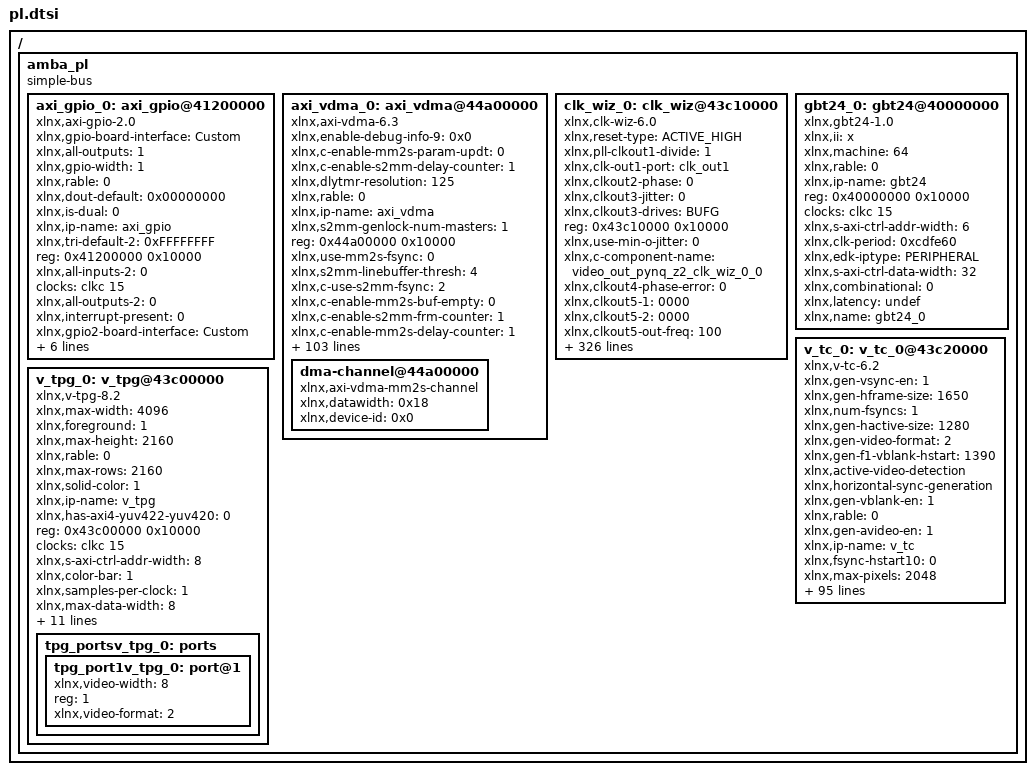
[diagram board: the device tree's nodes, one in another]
/ {
	amba_pl: amba_pl {
		ranges;
		compatible = "simple-bus";
		#address-cells = <1>;
		#size-cells = <1>;
		axi_gpio_0: axi_gpio@41200000 {
			xlnx,gpio-board-interface = "Custom";
			compatible = "xlnx,axi-gpio-2.0" , "xlnx,xps-gpio-1.00.a";
			xlnx,all-outputs = <1>;
			xlnx,gpio-width = <1>;
			xlnx,rable = <0>;
			xlnx,dout-default = <0x00000000>;
			xlnx,is-dual = <0>;
			xlnx,ip-name = "axi_gpio";
			xlnx,tri-default-2 = <0xFFFFFFFF>;
			reg = <0x41200000 0x10000>;
			xlnx,all-inputs-2 = <0>;
			clocks = <&clkc 15>;
			xlnx,all-outputs-2 = <0>;
			xlnx,interrupt-present = <0>;
			xlnx,gpio2-board-interface = "Custom";
			xlnx,edk-iptype = "PERIPHERAL";
			xlnx,dout-default-2 = <0x00000000>;
			xlnx,gpio2-width = <32>;
			status = "okay";
			clock-names = "s_axi_aclk";
			xlnx,tri-default = <0xFFFFFFFF>;
			xlnx,name = "axi_gpio_0";
			xlnx,all-inputs = <0>;
		};
		axi_vdma_0: axi_vdma@44a00000 {
			xlnx,enable-debug-info-9 = <0x0>;
			xlnx,c-enable-mm2s-param-updt = <0>;
			xlnx,c-enable-s2mm-delay-counter = <1>;
			xlnx,dlytmr-resolution = <125>;
			xlnx,rable = <0>;
			xlnx,ip-name = "axi_vdma";
			xlnx,s2mm-genlock-num-masters = <1>;
			reg = <0x44a00000 0x10000>;
			xlnx,use-mm2s-fsync = <0>;
			xlnx,s2mm-linebuffer-thresh = <4>;
			xlnx,c-use-s2mm-fsync = <2>;
			xlnx,c-enable-mm2s-buf-empty = <0>;
			xlnx,c-enable-s2mm-frm-counter = <1>;
			xlnx,c-enable-mm2s-delay-counter = <1>;
			xlnx,c-dlytmr-resolution = <125>;
			xlnx,c-enable-s2mm-buf-full = <0>;
			xlnx,dynamic-resolution = <1>;
			xlnx,s2mm-sof-enable = <0x1>;
			xlnx,mm2s-genlock-num-masters = <1>;
			xlnx,c-s2mm-genlock-num-masters = <1>;
			xlnx,c-enable-s2mm-fsync-out = <0>;
			xlnx,mm2s-linebuffer-thresh = <4>;
			xlnx,c-use-mm2s-fsync = <0>;
			xlnx,c-s2mm-linebuffer-thresh = <4>;
			xlnx,c-enable-mm2s-frm-counter = <1>;
			compatible = "xlnx,axi-vdma-6.3" , "xlnx,axi-vdma-1.00.a";
			xlnx,c-m-axis-mm2s-tdata-width = <24>;
			xlnx,c-enable-all = <0>;
			xlnx,s2mm-max-burst-length = <8>;
			xlnx,c-dynamic-resolution = <1>;
			xlnx,c-enable-s2mm-rst-out = <0>;
			xlnx,mm2s-sof-enable = <1>;
			xlnx,include-s2mm-dre = <0x0>;
			xlnx,c-s2mm-sof-enable = <1>;
			xlnx,c-enable-mm2s-fsync-out = <0>;
			xlnx,c-mm2s-genlock-num-masters = <1>;
			xlnx,c-mm2s-linebuffer-thresh = <4>;
			xlnx,c-enable-tstvec = <0>;
			xlnx,mm2s-max-burst-length = <8>;
			xlnx,c-s2mm-max-burst-length = <8>;
			status = "okay";
			xlnx,c-enable-mm2s-rst-out = <0>;
			xlnx,include-mm2s-dre = <0x0>;
			xlnx,c-include-s2mm-dre = <0>;
			xlnx,c-mm2s-sof-enable = <1>;
			xlnx,name = "axi_vdma_0";
			xlnx,c-enable-s2mm-frmstr-reg = <0>;
			xlnx,c-include-sg = <0>;
			xlnx,flush-on-fsync = <0x1>;
			xlnx,c-m-axi-s2mm-data-width = <64>;
			xlnx,c-enable-s2mm-sts-reg = <0>;
			xlnx,include-s2mm-sf = <1>;
			xlnx,c-mm2s-max-burst-length = <8>;
			xlnx,s2mm-linebuffer-depth = <0x200>;
			xlnx,include-s2mm = <0x0>;
			xlnx,c-include-mm2s-dre = <0>;
			clocks = <&clkc 15>, <&clkc 15>, <&clkc 15>;
			xlnx,c-enable-mm2s-frmstr-reg = <0>;
			xlnx,enable-debug-info-10 = <0>;
			xlnx,addrwidth = <0x20>;
			xlnx,enable-debug-info-11 = <0>;
			xlnx,enable-debug-info-12 = <0>;
			xlnx,edk-iptype = "PERIPHERAL";
			xlnx,c-flush-on-fsync = <1>;
			xlnx,c-m-axi-mm2s-data-width = <64>;
			xlnx,use-fsync = <1>;
			xlnx,s2mm-genlock-repeat-en = <1>;
			xlnx,enable-vert-flip = <0x0>;
			xlnx,enable-debug-info-13 = <0x0>;
			xlnx,include-mm2s-sf = <0>;
			xlnx,include-internal-genlock = <0x1>;
			xlnx,enable-debug-info-14 = <0x1>;
			xlnx,c-include-s2mm-sf = <1>;
			clock-names = "m_axi_mm2s_aclk" , "m_axis_mm2s_aclk" , "s_axi_lite_aclk";
			xlnx,enable-debug-info-15 = <0x1>;
			xlnx,mm2s-linebuffer-depth = <0x200>;
			xlnx,include-mm2s = <0x1>;
			xlnx,c-single-interface = <0>;
			xlnx,c-s2mm-linebuffer-depth = <512>;
			xlnx,c-addr-width = <32>;
			xlnx,c-include-s2mm = <0>;
			xlnx,s2mm-genlock-mode = <0x0>;
			xlnx,c-s-axis-s2mm-tdata-width = <32>;
			xlnx,flush-fsync = <0x1>;
			xlnx,select-xpm = <0>;
			xlnx,s2mm-data-width = <0x40>;
			xlnx,num-fstores = <0x3>;
			xlnx,enable-vidparam-reads = <0x1>;
			xlnx,mm2s-genlock-repeat-en = <0>;
			xlnx,c-use-fsync = <1>;
			xlnx,c-s2mm-genlock-repeat-en = <1>;
			xlnx,c-enable-vert-flip = <0>;
			xlnx,prmry-is-aclk-async = <0>;
			xlnx,c-include-internal-genlock = <1>;
			xlnx,c-include-mm2s-sf = <0>;
			xlnx,s2mm-tdata-width = <0x20>;
			xlnx,enable-vidprmtr-reads = <1>;
			xlnx,c-include-mm2s = <1>;
			xlnx,c-mm2s-linebuffer-depth = <512>;
			xlnx,mm2s-genlock-mode = <0x0>;
			xlnx,enable-debug-info-0 = <0>;
			xlnx,enable-debug-all = <0x0>;
			xlnx,c-s2mm-genlock-mode = <0>;
			xlnx,enable-debug-info-1 = <0x0>;
			xlnx,mm2s-data-width = <0x40>;
			xlnx,enable-debug-info-2 = <0>;
			xlnx,c-enable-s2mm-param-updt = <0>;
			xlnx,c-num-fstores = <3>;
			xlnx,enable-debug-info-3 = <0>;
			xlnx,enable-debug-info-4 = <0>;
			xlnx,c-mm2s-genlock-repeat-en = <0>;
			xlnx,enable-debug-info-5 = <0x0>;
			xlnx,c-prmry-is-aclk-async = <0>;
			xlnx,mm2s-tdata-width = <0x18>;
			xlnx,enable-debug-info-6 = <0x1>;
			xlnx,enable-debug-info-7 = <0x1>;
			xlnx,c-enable-vidprmtr-reads = <1>;
			xlnx,use-s2mm-fsync = <2>;
			xlnx,enable-debug-info-8 = <0>;
			xlnx,c-mm2s-genlock-mode = <0>;
			dma-channel@44a00000 {
				xlnx,datawidth = <0x18>;
				xlnx,device-id = <0x0>;
				compatible = "xlnx,axi-vdma-mm2s-channel";
			};
		};
		clk_wiz_0: clk_wiz@43c10000 {
			xlnx,reset-type = "ACTIVE_HIGH";
			xlnx,pll-clkout1-divide = <1>;
			xlnx,clk-out1-port = "clk_out1";
			xlnx,clkout2-phase = <0>;
			xlnx,clkout3-jitter = <0>;
			xlnx,clkout3-drives = "BUFG";
			reg = <0x43c10000 0x10000>;
			xlnx,use-min-o-jitter = <0>;
			xlnx,c-component-name = "video_out_pynq_z2_clk_wiz_0_0";
			xlnx,clkout4-phase-error = <0>;
			xlnx,clkout5-1 = <0000>;
			xlnx,clkout5-2 = <0000>;
			xlnx,clkout5-out-freq = <100>;
			xlnx,d-max = <80>;
			xlnx,clkout1-phase = <0>;
			xlnx,divide6-auto = <0x13880>;
			xlnx,clkout1-jitter = <0xea1f4d8>;
			xlnx,clkfb-in-n-port = "clkfb_in_n";
			xlnx,clkout2-requested-out-freq = <100>;
			xlnx,use-locked = <1>;
			xlnx,pll-clkout5-duty-cycle = <0x7a120>;
			xlnx,mmcm-clkout3-use-fine-ps;
			xlnx,clkout1-drives = "BUFG";
			xlnx,input-clk-stopped-port = "input_clk_stopped";
			xlnx,clkout4-duty-cycle = <50>;
			xlnx,divide3-auto = <0x13880>;
			xlnx,use-dyn-reconfig = <1>;
			xlnx,clkout3-actual-freq = <100>;
			xlnx,clkout6-requested-duty-cycle = <50>;
			xlnx,diff-clk-in1-board-interface = "Custom";
			xlnx,mmcm-clkout0-duty-cycle = <0x7a120>;
			xlnx,clkin2-jitter-ps = <100>;
			xlnx,clkout2-1 = <0000>;
			xlnx,in-freq-units = "Units_MHz";
			xlnx,clkout2-2 = <0000>;
			xlnx,feedback-source = "FDBK_AUTO";
			xlnx,clkout5-requested-out-freq = <100>;
			xlnx,name = "clk_wiz_0";
			xlnx,prim-in-freq = <100>;
			xlnx,mmcm-clkout5-divide = <1>;
			xlnx,clkout3-phase-error = <0>;
			xlnx,clk-in2-board-interface = "Custom";
			xlnx,clkin1-ui-jitter = <0x2710>;
			xlnx,use-inclk-switchover = <0>;
			clock-names = "clk_in1" , "s_axi_aclk";
			xlnx,clkout5-duty-cycle = <50>;
			xlnx,use-clkout4-bar = <0>;
			xlnx,mmcm-clkout1-duty-cycle = <0x7a120>;
			xlnx,mmcm-clkout2-use-fine-ps;
			xlnx,clkout2-out-freq = <100>;
			xlnx,use-dyn-phase-shift = <0>;
			xlnx,mmcm-clkout3-divide = <1>;
			xlnx,clkout2-actual-freq = <100>;
			xlnx,o-min = <1>;
			xlnx,daddr-port = "daddr";
			xlnx,precision = <1>;
			xlnx,mmcm-ref-jitter1 = <0x2710>;
			clock-output-names = "0x43c10000-clk_out1";
			xlnx,mmcm-ref-jitter2 = <0x2710>;
			xlnx,pll-notes = "No , notes";
			xlnx,use-phase-alignment = <1>;
			xlnx,ref-clk-freq = <100>;
			xlnx,clkout7-requested-duty-cycle = <50>;
			xlnx,inclk-sum-row0 = "Input , Clock , Freq , (MHz) , Input , Jitter , (UI)";
			xlnx,inclk-sum-row1 = "__primary_________100.000____________0.010";
			xlnx,use-fast-simulation = <0>;
			xlnx,inclk-sum-row2 = "no_secondary_input_clock";
			xlnx,mmcm-clkout1-divide = <1>;
			xlnx,din-port = "din";
			xlnx,reset-board-interface = "Custom";
			xlnx,clkout6-duty-cycle = <50>;
			xlnx,clkout2-phase-error = <0>;
			xlnx,clkout1-requested-duty-cycle = <50>;
			xlnx,vco-max = <1200>;
			xlnx,use-freq-synth = <1>;
			xlnx,primtype-sel = "AUTO";
			xlnx,mmcm-clkout2-duty-cycle = <0x7a120>;
			xlnx,clkout5-used = <0>;
			xlnx,d-min = <1>;
			xlnx,pll-clkfbout-mult = <1>;
			xlnx,mmcm-clkout4-cascade;
			xlnx,use-clkout1-bar = <0>;
			xlnx,clk-out6-port = "clk_out6";
			xlnx,clkout2-sequence-number = <1>;
			xlnx,clk-valid-port = "CLK_VALID";
			xlnx,clkout2-used = <0>;
			xlnx,clkout4-sequence-number = <1>;
			speed-grade = <1>;
			xlnx,psincdec-port = "psincdec";
			xlnx,mmcm-clkout1-use-fine-ps;
			xlnx,clk-out3-port = "clk_out3";
			xlnx,clkout6-sequence-number = <1>;
			xlnx,platform = "UNKNOWN";
			xlnx,mmcm-clkout6-phase = <0>;
			xlnx,clkout1-actual-freq = <100>;
			xlnx,clkout6-out-freq = <100>;
			xlnx,mmcm-clkin2-period = <10>;
			xlnx,prim-in-jitter = <0x2710>;
			xlnx,mmcm-clkfbout-mult-f = <0x2367b88>;
			status = "okay";
			xlnx,clkout6-1 = <0000>;
			xlnx,clkout6-2 = <0000>;
			xlnx,clkout7-duty-cycle = <50>;
			xlnx,outclk-sum-row1 = "clk_out1__74.25000______0.000______50.0______245.495____245.344";
			xlnx,outclk-sum-row2 = "no_CLK_OUT2_output";
			xlnx,jitter-sel = "No_Jitter";
			xlnx,outclk-sum-row3 = "no_CLK_OUT3_output";
			xlnx,mmcm-clkout5-phase = <0>;
			xlnx,mmcm-clkout3-duty-cycle = <0x7a120>;
			xlnx,outclk-sum-row4 = "no_CLK_OUT4_output";
			xlnx,clkfb-in-p-port = "clkfb_in_p";
			xlnx,outclk-sum-row5 = "no_CLK_OUT5_output";
			xlnx,outclk-sum-row6 = "no_CLK_OUT6_output";
			xlnx,outclk-sum-row7 = "no_CLK_OUT7_output";
			xlnx,clkout1-phase-error = <0xe9fa700>;
			xlnx,divide5-auto = <0x13880>;
			xlnx,pll-bandwidth = "OPTIMIZED";
			xlnx,psdone-port = "psdone";
			xlnx,clkout3-1 = <0000>;
			xlnx,clkout3-2 = <0000>;
			xlnx,clkout3-requested-out-freq = <100>;
			xlnx,edk-iptype = "PERIPHERAL";
			xlnx,pll-clkout4-divide = <1>;
			xlnx,pll-clkfbout-phase = <0>;
			xlnx,divide2-auto = <0x13880>;
			xlnx,override-mmcm = <0>;
			xlnx,clkout6-jitter = <0>;
			xlnx,ss-mode = "CENTER_HIGH";
			xlnx,mmcm-notes = "None";
			xlnx,mmcm-clkout0-use-fine-ps;
			xlnx,clkout6-drives = "BUFG";
			xlnx,mmcm-clkfbout-use-fine-ps;
			xlnx,ss-mod-period = <4000>;
			xlnx,mmcm-clkout4-phase = <0>;
			xlnx,clkout2-requested-duty-cycle = <50>;
			xlnx,clkout0-actual-freq = <0x46cf710>;
			xlnx,divclk = <0000>;
			xlnx,primary-port = "clk_in1";
			xlnx,mmcm-compensation = "ZHOLD";
			xlnx,clkout6-requested-out-freq = <100>;
			xlnx,clkout0-1 = <0000>;
			xlnx,clkout0-2 = <0000>;
			xlnx,clkout2-requested-phase = <0>;
			xlnx,relative-inclk = "REL_PRIMARY";
			xlnx,pll-clkout2-divide = <1>;
			xlnx,clkout4-requested-phase = <0>;
			xlnx,enable-user-clock0 = <0>;
			xlnx,filter-1 = <0000>;
			xlnx,mmcm-clkout4-duty-cycle = <0x7a120>;
			xlnx,clkout3-out-freq = <100>;
			xlnx,clkout4-jitter = <0>;
			xlnx,clkout6-requested-phase = <0>;
			xlnx,clkoutphy-requested-freq = <600>;
			xlnx,enable-user-clock1 = <0>;
			xlnx,filter-2 = <0000>;
			xlnx,ss-mod-freq = <250>;
			xlnx,mmcm-divclk-divide = <4>;
			xlnx,enable-user-clock2 = <0>;
			xlnx,in-jitter-units = "Units_UI";
			xlnx,enable-user-clock3 = <0>;
			xlnx,lock-1 = <0000>;
			xlnx,clkout4-drives = "BUFG";
			xlnx,lock-2 = <0000>;
			xlnx,den-port = "den";
			xlnx,lock-3 = <0000>;
			xlnx,use-safe-clock-startup = <0>;
			xlnx,mmcm-clkout3-phase = <0>;
			xlnx,dwe-port = "dwe";
			xlnx,clkfb-out-n-port = "clkfb_out_n";
			xlnx,use-max-i-jitter = <0>;
			xlnx,drdy-port = "drdy";
			xlnx,vco-min = <600>;
			xlnx,pll-clkout0-divide = <1>;
			xlnx,clkin1-jitter-ps = <100>;
			xlnx,clk-in-sel-port = "clk_in_sel";
			xlnx,use-freeze = <0>;
			xlnx,clkout2-jitter = <0>;
			xlnx,enable-pll0 = <0>;
			xlnx,enable-pll1 = <0>;
			xlnx,clkout2-drives = "BUFG";
			xlnx,use-inclk-stopped = <0>;
			xlnx,use-clkout3-bar = <0>;
			xlnx,use-clk-valid = <0>;
			xlnx,mmcm-clkout2-phase = <0>;
			compatible = "xlnx,clk-wiz-6.0" , "xlnx,clocking-wizard";
			xlnx,reset-port = "reset";
			xlnx,mmcm-clkout5-duty-cycle = <0x7a120>;
			xlnx,mmcm-clkout0-divide-f = <0xbebc20>;
			xlnx,pll-clkout0-duty-cycle = <0x7a120>;
			xlnx,diff-clk-in2-board-interface = "Custom";
			xlnx,clkout3-requested-duty-cycle = <50>;
			xlnx,use-status = <0>;
			xlnx,prim-source = "Single_ended_clock_capable_pin";
			xlnx,clkout7-used = <0>;
			xlnx,use-clkfb-stopped = <0>;
			xlnx,mmcm-clkout1-phase = <0>;
			xlnx,mmcm-clkout6-divide = <1>;
			xlnx,clkout7-out-freq = <100>;
			xlnx,prim-in-timeperiod = <10>;
			xlnx,clkout4-used = <0>;
			xlnx,pll-clkin-period = <1>;
			xlnx,clk-out5-port = "clk_out5";
			xlnx,psclk-port = "psclk";
			xlnx,primitive = "MMCM";
			xlnx,clkout1-used;
			xlnx,reset-low = <0>;
			xlnx,clk-in1-board-interface = "Custom";
			xlnx,clk-out2-port = "clk_out2";
			xlnx,power-down-port = "power_down";
			xlnx,clkout7-phase-error = <0>;
			xlnx,mmcm-clkout6-duty-cycle = <0x7a120>;
			xlnx,mmcm-clkout4-divide = <1>;
			xlnx,mmcm-clkfbout-phase = <0>;
			xlnx,mmcm-clkout0-phase = <0>;
			xlnx,pll-clkout1-duty-cycle = <0x7a120>;
			xlnx,user-clk-freq0 = <100>;
			xlnx,user-clk-freq1 = <100>;
			xlnx,pll-clkout5-phase = <0>;
			xlnx,user-clk-freq2 = <100>;
			xlnx,secondary-in-jitter = <0x2710>;
			xlnx,user-clk-freq3 = <100>;
			xlnx,use-clock-sequencing = <0>;
			xlnx,secondary-source = "Single_ended_clock_capable_pin";
			xlnx,cddcdone-port = "cddcdone";
			xlnx,clkout7-phase = <0>;
			xlnx,psen-port = "psen";
			xlnx,mmcm-clkout6-use-fine-ps;
			xlnx,dclk-port = "dclk";
			xlnx,m-max = <64>;
			xlnx,outclk-sum-row0a = "Output , Output , Phase , Duty , Cycle , Pk-to-Pk , Phase";
			xlnx,clkout1-requested-out-freq = <0x46cf710>;
			xlnx,clkout6-actual-freq = <100>;
			xlnx,divide7-auto = <0x13880>;
			xlnx,outclk-sum-row0b = "Clock , Freq , (MHz) , (degrees) , (%) , Jitter , (ps) , Error , (ps)";
			xlnx,clkout4-1 = <0000>;
			xlnx,locked-port = "locked";
			xlnx,mmcm-clkout2-divide = <1>;
			xlnx,clkin2-ui-jitter = <0x2710>;
			xlnx,clkout4-2 = <0000>;
			xlnx,enable-clock-monitor = <0>;
			xlnx,ss-mod-time = <0xfa0>;
			xlnx,auto-primitive = "MMCM";
			xlnx,divide4-auto = <0x13880>;
			xlnx,pll-clkout4-phase = <0>;
			xlnx,use-power-down = <0>;
			xlnx,mmcm-startup-wait;
			xlnx,divide1-auto = <1>;
			xlnx,clkout4-requested-duty-cycle = <50>;
			xlnx,clkout4-requested-out-freq = <100>;
			xlnx,rable = <0>;
			xlnx,optimize-clocking-structure-en = <0>;
			xlnx,clkout4-out-freq = <100>;
			xlnx,clkout6-phase = <0>;
			xlnx,num-out-clks = <1>;
			xlnx,ip-name = "clk_wiz";
			xlnx,pll-clkout2-duty-cycle = <0x7a120>;
			xlnx,clkout1-1 = <0000>;
			xlnx,clkout1-2 = <0000>;
			xlnx,clkout1-duty-cycle = <50>;
			xlnx,pll-divclk-divide = <1>;
			xlnx,clkout6-phase-error = <0>;
			xlnx,dout-port = "dout";
			xlnx,clkout1-sequence-number = <1>;
			xlnx,pll-clkout3-phase = <0>;
			xlnx,cddcreq-port = "cddcreq";
			xlnx,clkout7-requested-out-freq = <100>;
			xlnx,use-spread-spectrum = <0>;
			xlnx,clkout3-sequence-number = <1>;
			xlnx,clkout5-sequence-number = <1>;
			xlnx,summary-strings = "empty";
			xlnx,pll-compensation = "SYSTEM_SYNCHRONOUS";
			xlnx,clkout5-phase = <0>;
			xlnx,clkout7-sequence-number = <1>;
			xlnx,status-port = "STATUS";
			xlnx,clkfb-out-p-port = "clkfb_out_p";
			xlnx,mmcm-clkout5-use-fine-ps;
			xlnx,clkfb-in-port = "clkfb_in";
			xlnx,clkout5-actual-freq = <100>;
			xlnx,input-mode = "frequency";
			xlnx,interface-selection = <1>;
			xlnx,mmcm-bandwidth = "OPTIMIZED";
			xlnx,calc-done = "empty";
			xlnx,pll-clkout2-phase = <0>;
			xlnx,has-cddc = <0>;
			xlnx,power-reg = <0000>;
			xlnx,mmcm-clkin1-period = <10>;
			xlnx,pll-clkout3-duty-cycle = <0x7a120>;
			xlnx,clkout2-duty-cycle = <50>;
			xlnx,clkout4-phase = <0>;
			xlnx,pll-clkout5-divide = <1>;
			xlnx,clkout7-jitter = <0>;
			clocks = <&clkc 15>, <&clkc 15>;
			xlnx,clkout1-out-freq = <0x46cf710>;
			xlnx,clkout7-drives = "BUFG";
			xlnx,clkout5-phase-error = <0>;
			xlnx,pll-clkout1-phase = <0>;
			xlnx,clkout5-requested-duty-cycle = <50>;
			xlnx,clkfb-in-signaling = "SINGLE";
			xlnx,enable-clkoutphy = <0>;
			xlnx,use-clkout2-bar = <0>;
			xlnx,secondary-port = "clk_in2";
			xlnx,clkout3-phase = <0>;
			xlnx,pll-clkout3-divide = <1>;
			xlnx,use-reset = <1>;
			xlnx,override-pll = <0>;
			xlnx,clkoutphy-mode = "VCO";
			xlnx,mmcm-clkout4-use-fine-ps;
			xlnx,clkout5-jitter = <0>;
			xlnx,clkout6-used = <0>;
			xlnx,m-min = <2>;
			xlnx,mmcm-clock-hold;
			xlnx,clkfb-stopped-port = "clkfb_stopped";
			xlnx,clk-out7-port = "clk_out7";
			xlnx,clkout1-requested-phase = <0>;
			xlnx,clkout4-actual-freq = <100>;
			xlnx,pll-clk-feedback = "CLKFBOUT";
			xlnx,phaseshift-mode = "WAVEFORM";
			xlnx,clkfb-out-port = "clkfb_out";
			xlnx,clkout5-drives = "BUFG";
			xlnx,o-max = <128>;
			xlnx,clkout3-requested-phase = <0>;
			xlnx,secondary-in-timeperiod = <10>;
			xlnx,pll-clkout4-duty-cycle = <0x7a120>;
			xlnx,clkout3-used = <0>;
			xlnx,jitter-options = "UI";
			xlnx,clkout5-requested-phase = <0>;
			xlnx,pll-clkout0-phase = <0>;
			xlnx,clk-out4-port = "clk_out4";
			xlnx,clkout3-duty-cycle = <50>;
			xlnx,clkout7-requested-phase = <0>;
			xlnx,secondary-in-freq = <100>;
			xlnx,use-min-power = <0>;
			xlnx,clkfbout-1 = <0000>;
			#clock-cells = <1>;
			xlnx,pll-ref-jitter = <0x2710>;
			xlnx,clkfbout-2 = <0000>;
		};
		gbt24_0: gbt24@40000000 {
			compatible = "xlnx,gbt24-1.0";
			xlnx,ii = "x";
			xlnx,machine = <64>;
			xlnx,rable = <0>;
			xlnx,ip-name = "gbt24";
			reg = <0x40000000 0x10000>;
			clocks = <&clkc 15>;
			xlnx,s-axi-ctrl-addr-width = <6>;
			xlnx,clk-period = <0xcdfe60>;
			xlnx,edk-iptype = "PERIPHERAL";
			status = "okay";
			clock-names = "ap_clk";
			xlnx,s-axi-ctrl-data-width = <32>;
			xlnx,combinational = <0>;
			xlnx,latency = "undef";
			xlnx,name = "gbt24_0";
		};
		v_tc_0: v_tc_0@43c20000 {
			xlnx,gen-vsync-en = <1>;
			xlnx,gen-hframe-size = <1650>;
			xlnx,num-fsyncs = <1>;
			xlnx,gen-hactive-size = <1280>;
			xlnx,gen-video-format = <2>;
			xlnx,gen-f1-vblank-hstart = <1390>;
			xlnx,active-video-detection;
			xlnx,horizontal-sync-generation;
			xlnx,gen-vblank-en = <1>;
			xlnx,rable = <0>;
			xlnx,gen-avideo-en = <1>;
			xlnx,ip-name = "v_tc";
			xlnx,fsync-hstart10 = <0>;
			xlnx,max-pixels = <2048>;
			xlnx,gen-fieldid-en = <0>;
			reg = <0x43c20000 0x10000>;
			xlnx,det-vblank-en = <1>;
			xlnx,fsync-hstart11 = <0>;
			xlnx,fsync-hstart12 = <0>;
			xlnx,gen-interlaced = <0>;
			xlnx,det-avideo-en = <1>;
			xlnx,fsync-hstart13 = <0>;
			xlnx,fsync-hstart14 = <0>;
			xlnx,gen-f0-vblank-hend = <1390>;
			xlnx,fsync-hstart15 = <0>;
			xlnx,det-hsync-en = <1>;
			xlnx,gen-avideo-polarity = <1>;
			xlnx,enable-generation;
			xlnx,max-lines-per-frame = <1024>;
			xlnx,has-axi4-lite = <1>;
			compatible = "xlnx,v-tc-6.2" , "xlnx,v-tc-6.1";
			xlnx,max-clocks-per-line = <2048>;
			xlnx,gen-f0-vframe-size = <750>;
			xlnx,gen-f0-vblank-hstart = <1390>;
			xlnx,max-lines = <1024>;
			xlnx,gen-f0-vsync-vstart = <724>;
			xlnx,horizontal-blank-generation;
			xlnx,gen-hsync-end = <1430>;
			xlnx,gen-f0-vsync-hstart = <1390>;
			xlnx,gen-f1-vsync-hend = <1390>;
			xlnx,vertical-blank-detection;
			xlnx,gen-vsync-polarity = <1>;
			xlnx,fsync-vstart0 = <0>;
			xlnx,gen-hsync-polarity = <1>;
			xlnx,fsync-vstart1 = <0>;
			status = "okay";
			xlnx,fsync-vstart2 = <0>;
			xlnx,gen-hsync-start = <1390>;
			xlnx,gen-f0-vsync-vend = <729>;
			xlnx,fsync-vstart3 = <0>;
			xlnx,vertical-sync-detection;
			xlnx,frame-syncs = <1>;
			xlnx,fsync-vstart4 = <0>;
			xlnx,gen-vactive-size = <720>;
			xlnx,name = "v_tc_0";
			xlnx,fsync-vstart5 = <0>;
			xlnx,gen-achroma-en = <0>;
			xlnx,fsync-vstart6 = <0>;
			xlnx,fsync-vstart7 = <0>;
			xlnx,det-fieldid-en = <0>;
			xlnx,gen-hsync-en = <1>;
			xlnx,fsync-vstart8 = <0>;
			xlnx,fsync-vstart9 = <0>;
			xlnx,fsync-vstart10 = <0>;
			xlnx,fsync-vstart11 = <0>;
			xlnx,arbitrary-res-en = <0>;
			xlnx,fsync-vstart12 = <0>;
			xlnx,fsync-vstart13 = <0>;
			clocks = <&clk_wiz_0 0>, <&clkc 15>;
			xlnx,fsync-vstart14 = <0>;
			xlnx,fsync-vstart15 = <0>;
			xlnx,gen-cparity = <0>;
			xlnx,edk-iptype = "PERIPHERAL";
			xlnx,vertical-sync-generation;
			xlnx,gen-f1-vblank-hend = <1390>;
			xlnx,det-vsync-en = <1>;
			xlnx,gen-vblank-polarity = <1>;
			xlnx,fsync-hstart0 = <0>;
			clock-names = "clk" , "s_axi_aclk";
			xlnx,interlace-en = <0>;
			xlnx,gen-auto-switch = <0>;
			xlnx,fsync-hstart1 = <0>;
			xlnx,fsync-hstart2 = <0>;
			xlnx,active-video-generation;
			xlnx,fsync-hstart3 = <0>;
			xlnx,fsync-hstart4 = <0>;
			xlnx,horizontal-blank-detection;
			xlnx,fsync-hstart5 = <0>;
			xlnx,gen-f1-vframe-size = <750>;
			xlnx,fsync-hstart6 = <0>;
			xlnx,fsync-hstart7 = <0>;
			xlnx,fsync-hstart8 = <0>;
			xlnx,gen-hblank-en = <1>;
			xlnx,fsync-hstart9 = <0>;
			xlnx,horizontal-sync-detection;
			xlnx,gen-f1-vsync-vend = <729>;
			xlnx,detect-en = <0>;
			xlnx,det-hblank-en = <1>;
			xlnx,vid-ppc = <4>;
			xlnx,has-intc-if = <0>;
			xlnx,generate-en = <1>;
			xlnx,gen-achroma-polarity = <1>;
			xlnx,sync-en = <0>;
			xlnx,det-achroma-en = <0>;
			xlnx,generator;
			xlnx,gen-f1-vsync-vstart = <724>;
			xlnx,vertical-blank-generation;
			xlnx,gen-hblank-polarity = <1>;
			xlnx,video-mode = "720p";
			xlnx,gen-fieldid-polarity = <1>;
			xlnx,gen-f1-vsync-hstart = <1390>;
			xlnx,gen-f0-vsync-hend = <1390>;
		};
		v_tpg_0: v_tpg@43c00000 {
			compatible = "xlnx,v-tpg-8.2" , "xlnx,v-tpg-8.0";
			xlnx,max-width = <4096>;
			xlnx,foreground = <1>;
			xlnx,max-height = <2160>;
			xlnx,rable = <0>;
			xlnx,max-rows = <2160>;
			xlnx,solid-color = <1>;
			xlnx,ip-name = "v_tpg";
			xlnx,has-axi4-yuv422-yuv420 = <0>;
			reg = <0x43c00000 0x10000>;
			clocks = <&clkc 15>;
			xlnx,s-axi-ctrl-addr-width = <8>;
			xlnx,color-bar = <1>;
			xlnx,samples-per-clock = <1>;
			xlnx,max-data-width = <8>;
			xlnx,has-axi4s-slave = <0>;
			xlnx,ppc = <1>;
			xlnx,max-cols = <4096>;
			xlnx,edk-iptype = "PERIPHERAL";
			status = "okay";
			clock-names = "ap_clk";
			xlnx,zone-plate = <1>;
			xlnx,num-video-components = <3>;
			xlnx,s-axi-ctrl-data-width = <32>;
			xlnx,ramp = <1>;
			xlnx,color-sweep = <1>;
			xlnx,display-port = <1>;
			xlnx,name = "v_tpg_0";
			tpg_portsv_tpg_0: ports {
				#address-cells = <1>;
				#size-cells = <0>;
				tpg_port1v_tpg_0: port@1 {
					xlnx,video-width = <8>;
					reg = <1>;
					xlnx,video-format = <2>;
				};
			};
		};
	};
};
